AUTOSAR XML (schema 4-2-2)
package /ComponentTypes
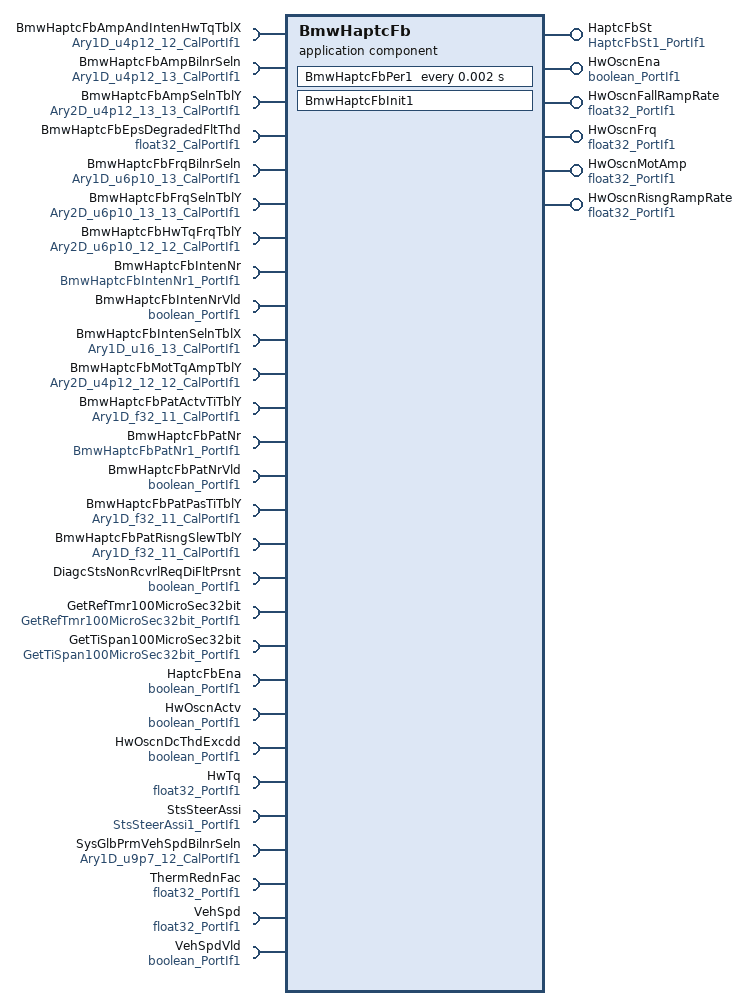
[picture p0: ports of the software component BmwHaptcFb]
  application sw component type BmwHaptcFb
    6 x provide port:
      HaptcFbSt: nonqueued-sender-com-spec{data-element=Val, init-value=14}, provided-interface=HaptcFbSt1_PortIf1
      HwOscnEna: nonqueued-sender-com-spec{data-element=Logl, init-value=0}, provided-interface=boolean_PortIf1
      HwOscnFallRampRate: nonqueued-sender-com-spec{data-element=Val, init-value=-4400}, provided-interface=float32_PortIf1
      HwOscnFrq: nonqueued-sender-com-spec{data-element=Val, init-value=50}, provided-interface=float32_PortIf1
      HwOscnMotAmp: nonqueued-sender-com-spec{data-element=Val, init-value=0}, provided-interface=float32_PortIf1
      HwOscnRisngRampRate: nonqueued-sender-com-spec{data-element=Val, init-value=4400}, provided-interface=float32_PortIf1
    28 x require port:
      BmwHaptcFbAmpAndIntenHwTqTblX: parameter-require-com-spec{init-value=[0, 4096, 8192, 12288, 16384, 20480, 24576, 28672, 32768, 36864, 38912, 40960], parameter=Ary1D}, required-interface=Ary1D_u4p12_12_CalPortIf1
      BmwHaptcFbAmpBilnrSeln: parameter-require-com-spec{init-value=[0, 4096, 8192, 12288, 16384, 20480, 24576, 28672, 32768, 36864, 40960, 40960, 40960], parameter=Ary1D}, required-interface=Ary1D_u4p12_13_CalPortIf1
      BmwHaptcFbAmpSelnTblY: parameter-require-com-spec{init-value=13 x [0, 40960, 40960, 40960, 40960, 40960, 40960, 40960, 40960, 40960, 40960, 40960, 40960], parameter=Ary2D}, required-interface=Ary2D_u4p12_13_13_CalPortIf1
      BmwHaptcFbEpsDegradedFltThd: parameter-require-com-spec{init-value=0.9, parameter=Val}, required-interface=float32_CalPortIf1
      BmwHaptcFbFrqBilnrSeln: parameter-require-com-spec{init-value=[30720, 10240, 30720, 10240, 40960, 40960, 40960, 20480, 20480, 46080, 20480, 46080, 51200], parameter=Ary1D}, required-interface=Ary1D_u6p10_13_CalPortIf1
      BmwHaptcFbFrqSelnTblY: parameter-require-com-spec{init-value=[[30720, 10240, 30720, 10240, 40960, 40960, 40960, 20480, 20480, 46080, 20480, 46080, 51200], [31744, 12288, 31744, 13312, 41984, 30720, 30720, 40960, 20480, 15360, 15360, 46080, 51200], [32768, 14336, 32768, 16384, 43008, 51200, 51200, 20480, 20480, 20480, 46080, 46080, 51200], [33792, 16384, 33792, 18432, 44032, 20480, 20480, 15360, 15360, 15360, 18432, 46080, 51200], [34816, 17408, 34816, 20480, 45056, 10240, 15360, 46080, 46080, 18432, 15360, 46080, 51200], [17408, 18432, 35840, 22528, 46080, 15360, 51200, 18432, 18432, 15360, 51200, 15360, 51200], [19456, 19456, 36864, 24576, 47104, 51200, 46080, 51200, 51200, 20480, 51200, 15360, 51200], [20480, 20480, 37888, 26624, 48128, 18432, 18432, 18432, 51200, 18432, 51200, 18432, 51200], [30720, 21504, 38912, 28672, 49152, 28672, 51200, 46080, 20480, 18432, 51200, 18432, 51200], [30720, 22528, 39936, 30720, 51200, 46080, 20480, 30720, 18432, 18432, 51200, 18432, 51200], [30720, 22528, 39936, 30720, 51200, 46080, 20480, 30720, 18432, 18432, 51200, 18432, 51200], [30720, 22528, 39936, 30720, 51200, 46080, 20480, 30720, 18432, 18432, 51200, 18432, 51200], [30720, 22528, 39936, 30720, 51200, 46080, 20480, 30720, 18432, 18432, 51200, 18432, 51200]], parameter=Ary2D}, required-interface=Ary2D_u6p10_13_13_CalPortIf1
      BmwHaptcFbHwTqFrqTblY: parameter-require-com-spec{init-value=[[30720, 10240, 30720, 10240, 40960, 40960, 40960, 20480, 20480, 46080, 20480, 46080], [31744, 12288, 31744, 13312, 41984, 30720, 30720, 40960, 20480, 15360, 15360, 46080], [32768, 14336, 32768, 16384, 43008, 51200, 51200, 20480, 20480, 20480, 46080, 46080], [33792, 16384, 33792, 18432, 44032, 20480, 20480, 15360, 15360, 15360, 18432, 46080], [34816, 17408, 34816, 20480, 45056, 10240, 15360, 46080, 46080, 18432, 15360, 46080], [17408, 18432, 35840, 22528, 46080, 15360, 51200, 18432, 18432, 15360, 51200, 15360], [19456, 19456, 36864, 24576, 47104, 51200, 46080, 51200, 51200, 20480, 51200, 15360], [20480, 20480, 37888, 26624, 48128, 18432, 18432, 18432, 51200, 18432, 51200, 18432], [30720, 21504, 38912, 28672, 49152, 28672, 51200, 46080, 20480, 18432, 51200, 18432], [30720, 22528, 39936, 30720, 51200, 46080, 20480, 30720, 18432, 18432, 51200, 18432], [30720, 22528, 39936, 30720, 51200, 46080, 20480, 30720, 18432, 18432, 51200, 18432], [30720, 22528, 39936, 30720, 51200, 46080, 20480, 30720, 18432, 18432, 51200, 18432]], parameter=Ary2D}, required-interface=Ary2D_u6p10_12_12_CalPortIf1
      BmwHaptcFbIntenNr: nonqueued-receiver-com-spec{data-element=Val, filter=data-filter-type=ALWAYS, init-value=15}, required-interface=BmwHaptcFbIntenNr1_PortIf1
      BmwHaptcFbIntenNrVld: nonqueued-receiver-com-spec{data-element=Logl, filter=data-filter-type=ALWAYS, init-value=0}, required-interface=boolean_PortIf1
      BmwHaptcFbIntenSelnTblX: parameter-require-com-spec{init-value=[0, 1, 2, 3, 4, 5, 6, 7, 8, 9, 10, 11, 12], parameter=Ary1D}, required-interface=Ary1D_u16_13_CalPortIf1
      BmwHaptcFbMotTqAmpTblY: parameter-require-com-spec{init-value=12 x [0, 1229, 1229, 1229, 1229, 1229, 1229, 1229, 1229, 1229, 1229, 1229], parameter=Ary2D}, required-interface=Ary2D_u4p12_12_12_CalPortIf1
      BmwHaptcFbPatActvTiTblY: parameter-require-com-spec{init-value=[0, 0.1, 0.2, 0.3, 0.4, 0.5, 0.6, 0.7, 0.8, 0.9, 3], parameter=Ary1D}, required-interface=Ary1D_f32_11_CalPortIf1
      BmwHaptcFbPatNr: nonqueued-receiver-com-spec{data-element=Val, filter=data-filter-type=ALWAYS, init-value=15}, required-interface=BmwHaptcFbPatNr1_PortIf1
      BmwHaptcFbPatNrVld: nonqueued-receiver-com-spec{data-element=Logl, filter=data-filter-type=ALWAYS, init-value=0}, required-interface=boolean_PortIf1
      BmwHaptcFbPatPasTiTblY: parameter-require-com-spec{init-value=[0, 0, 0.1, 0.2, 0.3, 0.4, 0.5, 0.6, 0.7, 0.8, 1], parameter=Ary1D}, required-interface=Ary1D_f32_11_CalPortIf1
      BmwHaptcFbPatRisngSlewTblY: parameter-require-com-spec{init-value=[0.1, 24.4, 13.2, 10, 15, 5, 10, 15, 20, 26, 30], parameter=Ary1D}, required-interface=Ary1D_f32_11_CalPortIf1
      DiagcStsNonRcvrlReqDiFltPrsnt: nonqueued-receiver-com-spec{data-element=Logl, filter=data-filter-type=ALWAYS, init-value=0}, required-interface=boolean_PortIf1
      GetRefTmr100MicroSec32bit: client-com-spec=Oper, required-interface=GetRefTmr100MicroSec32bit_PortIf1
      GetTiSpan100MicroSec32bit: client-com-spec=Oper, required-interface=GetTiSpan100MicroSec32bit_PortIf1
      HaptcFbEna: nonqueued-receiver-com-spec{data-element=Logl, filter=data-filter-type=ALWAYS, init-value=1}, required-interface=boolean_PortIf1
      HwOscnActv: nonqueued-receiver-com-spec{data-element=Logl, filter=data-filter-type=ALWAYS, init-value=0}, required-interface=boolean_PortIf1
      HwOscnDcThdExcdd: nonqueued-receiver-com-spec{data-element=Logl, filter=data-filter-type=ALWAYS, init-value=0}, required-interface=boolean_PortIf1
      HwTq: nonqueued-receiver-com-spec{data-element=Val, filter=data-filter-type=ALWAYS, init-value=0}, required-interface=float32_PortIf1
      StsSteerAssi: nonqueued-receiver-com-spec{data-element=Val, filter=data-filter-type=ALWAYS, init-value=0}, required-interface=StsSteerAssi1_PortIf1
      SysGlbPrmVehSpdBilnrSeln: parameter-require-com-spec{init-value=[0, 640, 1920, 3840, 7680, 10240, 12800, 15360, 19200, 23040, 25600, 28160], parameter=Ary1D}, required-interface=Ary1D_u9p7_12_CalPortIf1
      ThermRednFac: nonqueued-receiver-com-spec{data-element=Val, filter=data-filter-type=ALWAYS, init-value=0}, required-interface=float32_PortIf1
      VehSpd: nonqueued-receiver-com-spec{data-element=Val, filter=data-filter-type=ALWAYS, init-value=0}, required-interface=float32_PortIf1
      VehSpdVld: nonqueued-receiver-com-spec{data-element=Logl, filter=data-filter-type=ALWAYS, init-value=0}, required-interface=boolean_PortIf1
    behavior BmwHaptcFb_InternalBehavior
      ar-typed-per-instance-memorys:
        data CurrInten: sw-calibration-access=READ-ONLY, type=BmwHaptcFbIntenNr1
        data CurrPat: sw-calibration-access=READ-ONLY, type=BmwHaptcFbPatNr1
        data TqOscnEnaTmr: sw-calibration-access=READ-ONLY, type=uint32
      init event BmwHaptcFb_InitEvent: start-on-event=BmwHaptcFbInit1
      timing event TMT_BmwHaptcFbPer1: start-on-event=BmwHaptcFbPer1, period=0.002
      port-api-options:
        enable-take-address=false, error-handling=NO-TRANSFORMER-ERROR-HANDLING, indirect-api=false, port=BmwHaptcFbAmpAndIntenHwTqTblX
        enable-take-address=false, error-handling=NO-TRANSFORMER-ERROR-HANDLING, indirect-api=false, port=BmwHaptcFbAmpBilnrSeln
        enable-take-address=false, error-handling=NO-TRANSFORMER-ERROR-HANDLING, indirect-api=false, port=BmwHaptcFbAmpSelnTblY
        enable-take-address=false, error-handling=NO-TRANSFORMER-ERROR-HANDLING, indirect-api=false, port=BmwHaptcFbEpsDegradedFltThd
        enable-take-address=false, error-handling=NO-TRANSFORMER-ERROR-HANDLING, indirect-api=false, port=BmwHaptcFbFrqBilnrSeln
        enable-take-address=false, error-handling=NO-TRANSFORMER-ERROR-HANDLING, indirect-api=false, port=BmwHaptcFbFrqSelnTblY
        enable-take-address=false, error-handling=NO-TRANSFORMER-ERROR-HANDLING, indirect-api=false, port=BmwHaptcFbHwTqFrqTblY
        enable-take-address=false, error-handling=NO-TRANSFORMER-ERROR-HANDLING, indirect-api=false, port=BmwHaptcFbIntenNr
        enable-take-address=false, error-handling=NO-TRANSFORMER-ERROR-HANDLING, indirect-api=false, port=BmwHaptcFbIntenNrVld
        enable-take-address=false, error-handling=NO-TRANSFORMER-ERROR-HANDLING, indirect-api=false, port=BmwHaptcFbIntenSelnTblX
        enable-take-address=false, error-handling=NO-TRANSFORMER-ERROR-HANDLING, indirect-api=false, port=BmwHaptcFbMotTqAmpTblY
        enable-take-address=false, error-handling=NO-TRANSFORMER-ERROR-HANDLING, indirect-api=false, port=BmwHaptcFbPatActvTiTblY
        enable-take-address=false, error-handling=NO-TRANSFORMER-ERROR-HANDLING, indirect-api=false, port=BmwHaptcFbPatNr
        enable-take-address=false, error-handling=NO-TRANSFORMER-ERROR-HANDLING, indirect-api=false, port=BmwHaptcFbPatNrVld
        enable-take-address=false, error-handling=NO-TRANSFORMER-ERROR-HANDLING, indirect-api=false, port=BmwHaptcFbPatPasTiTblY
        enable-take-address=false, error-handling=NO-TRANSFORMER-ERROR-HANDLING, indirect-api=false, port=DiagcStsNonRcvrlReqDiFltPrsnt
        enable-take-address=false, error-handling=NO-TRANSFORMER-ERROR-HANDLING, indirect-api=false, port=GetRefTmr100MicroSec32bit
        enable-take-address=false, error-handling=NO-TRANSFORMER-ERROR-HANDLING, indirect-api=false, port=GetTiSpan100MicroSec32bit
        enable-take-address=false, error-handling=NO-TRANSFORMER-ERROR-HANDLING, indirect-api=false, port=HaptcFbEna
        enable-take-address=false, error-handling=NO-TRANSFORMER-ERROR-HANDLING, indirect-api=false, port=HaptcFbSt
        enable-take-address=false, error-handling=NO-TRANSFORMER-ERROR-HANDLING, indirect-api=false, port=HwOscnActv
        enable-take-address=false, error-handling=NO-TRANSFORMER-ERROR-HANDLING, indirect-api=false, port=HwOscnDcThdExcdd
        enable-take-address=false, error-handling=NO-TRANSFORMER-ERROR-HANDLING, indirect-api=false, port=HwOscnEna
        enable-take-address=false, error-handling=NO-TRANSFORMER-ERROR-HANDLING, indirect-api=false, port=HwOscnFallRampRate
        enable-take-address=false, error-handling=NO-TRANSFORMER-ERROR-HANDLING, indirect-api=false, port=HwOscnFrq
        enable-take-address=false, error-handling=NO-TRANSFORMER-ERROR-HANDLING, indirect-api=false, port=HwOscnMotAmp
        enable-take-address=false, error-handling=NO-TRANSFORMER-ERROR-HANDLING, indirect-api=false, port=HwOscnRisngRampRate
        enable-take-address=false, error-handling=NO-TRANSFORMER-ERROR-HANDLING, indirect-api=false, port=HwTq
        enable-take-address=false, error-handling=NO-TRANSFORMER-ERROR-HANDLING, indirect-api=false, port=StsSteerAssi
        enable-take-address=false, error-handling=NO-TRANSFORMER-ERROR-HANDLING, indirect-api=false, port=SysGlbPrmVehSpdBilnrSeln
        enable-take-address=false, error-handling=NO-TRANSFORMER-ERROR-HANDLING, indirect-api=false, port=ThermRednFac
        enable-take-address=false, error-handling=NO-TRANSFORMER-ERROR-HANDLING, indirect-api=false, port=VehSpd
        enable-take-address=false, error-handling=NO-TRANSFORMER-ERROR-HANDLING, indirect-api=false, port=VehSpdVld
      runnable BmwHaptcFbInit1
      runnable BmwHaptcFbPer1
        data-receive-point-by-arguments:
          13 x access:
            REC_BmwHaptcFbIntenNr_Val: accessed-variable=BmwHaptcFbIntenNr.Val
            REC_BmwHaptcFbIntenNrVld_Logl: accessed-variable=BmwHaptcFbIntenNrVld.Logl
            REC_BmwHaptcFbPatNr_Val: accessed-variable=BmwHaptcFbPatNr.Val
            REC_BmwHaptcFbPatNrVld_Logl: accessed-variable=BmwHaptcFbPatNrVld.Logl
            REC_DiagcStsNonRcvrlReqDiFltPrsnt_Logl: accessed-variable=DiagcStsNonRcvrlReqDiFltPrsnt.Logl
            REC_HaptcFbEna_Logl: accessed-variable=HaptcFbEna.Logl
            REC_HwOscnActv_Logl: accessed-variable=HwOscnActv.Logl
            REC_HwOscnDcThdExcdd_Logl: accessed-variable=HwOscnDcThdExcdd.Logl
            REC_HwTq_Val: accessed-variable=HwTq.Val
            REC_StsSteerAssi_Val: accessed-variable=StsSteerAssi.Val
            REC_ThermRednFac_Val: accessed-variable=ThermRednFac.Val
            REC_VehSpd_Val: accessed-variable=VehSpd.Val
            REC_VehSpdVld_Logl: accessed-variable=VehSpdVld.Logl
        data-send-points:
          6 x access:
            SEND_HaptcFbSt_Val: accessed-variable=HaptcFbSt.Val
            SEND_HwOscnEna_Logl: accessed-variable=HwOscnEna.Logl
            SEND_HwOscnFallRampRate_Val: accessed-variable=HwOscnFallRampRate.Val
            SEND_HwOscnFrq_Val: accessed-variable=HwOscnFrq.Val
            SEND_HwOscnMotAmp_Val: accessed-variable=HwOscnMotAmp.Val
            SEND_HwOscnRisngRampRate_Val: accessed-variable=HwOscnRisngRampRate.Val
        sync call SC_GetRefTmr100MicroSec32bit_Oper: operation=GetRefTmr100MicroSec32bit.Oper, timeout=0
        sync call SC_GetTiSpan100MicroSec32bit_Oper: operation=GetTiSpan100MicroSec32bit.Oper, timeout=0
  swc implementation BmwHaptcFb_Implementation: behavior=BmwHaptcFb_InternalBehavior
    code-descriptors:
      code Default: artifact-descriptors=autosar-engineering-object={short-label=Default, category=SWSRC}
